VERSION ""

NS_ :

BS_:

BU_: EPS ABS ENGINE BCM RADAR CAMERA XXX

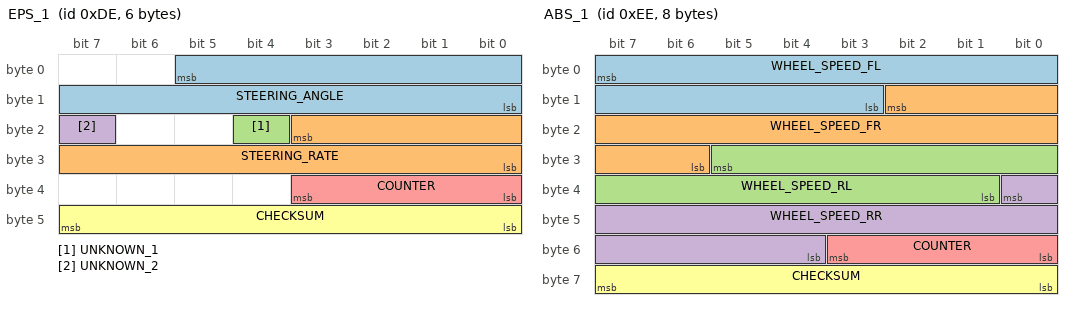
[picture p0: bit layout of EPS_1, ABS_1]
BO_ 222 EPS_1: 6 EPS
 SG_ STEERING_ANGLE : 5|14@0+ (0.1,-716.8) [-716.8|921.5] "deg" XXX
 SG_ STEERING_RATE : 19|12@0+ (1,-2000) [-2000|2095] "deg/s" XXX
 SG_ UNKNOWN_1 : 20|1@0+ (1,0) [0|1] "" XXX
 SG_ UNKNOWN_2 : 23|1@0+ (1,0) [0|1] "" XXX
 SG_ COUNTER : 35|4@0+ (1,0) [0|15] "" XXX
 SG_ CHECKSUM : 47|8@0+ (1,0) [0|255] "" XXX

BO_ 238 ABS_1: 8 ABS
 SG_ WHEEL_SPEED_FL : 7|13@0+ (0.017,0) [0|139.247] "m/s" XXX
 SG_ WHEEL_SPEED_FR : 10|13@0+ (0.017,0) [0|139.247] "m/s" XXX
 SG_ WHEEL_SPEED_RL : 29|13@0+ (0.017,0) [0|139.247] "m/s" XXX
 SG_ WHEEL_SPEED_RR : 32|13@0+ (0.017,0) [0|139.247] "m/s" XXX
 SG_ COUNTER : 51|4@0+ (1,0) [0|15] "" XXX
 SG_ CHECKSUM : 63|8@0+ (1,0) [0|255] "" XXX

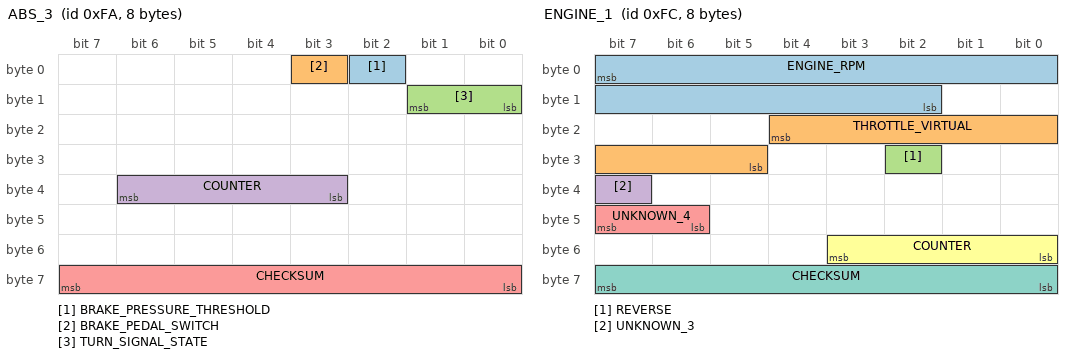
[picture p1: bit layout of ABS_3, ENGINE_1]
BO_ 250 ABS_3: 8 ABS
 SG_ BRAKE_PRESSURE_THRESHOLD : 2|1@0+ (1,0) [0|1] "" XXX
 SG_ BRAKE_PEDAL_SWITCH : 3|1@0+ (1,0) [0|1] "" XXX
 SG_ TURN_SIGNAL_STATE : 9|2@0+ (1,0) [0|3] "" XXX
 SG_ COUNTER : 38|4@0+ (1,0) [0|15] "" XXX
 SG_ CHECKSUM : 63|8@0+ (1,0) [0|255] "" XXX

BO_ 252 ENGINE_1: 8 ENGINE
 SG_ ENGINE_RPM : 7|14@0+ (1,0) [0|16383] "rev/min" XXX
 SG_ THROTTLE_VIRTUAL : 20|8@0+ (0.4,0) [0|102] "percent" XXX
 SG_ REVERSE : 26|1@0+ (1,0) [0|1] "" XXX
 SG_ UNKNOWN_3 : 39|1@0+ (1,0) [0|1] "" XXX
 SG_ UNKNOWN_4 : 46|2@1+ (1,0) [0|3] "" XXX
 SG_ COUNTER : 51|4@0+ (1,0) [0|15] "" XXX
 SG_ CHECKSUM : 63|8@0+ (1,0) [0|255] "" XXX

BO_ 496 ACCEL_PEDAL_DRIVER: 8 ENGINE
 SG_ ACCEL_PEDAL_DRIVER : 3|7@0+ (0.408,0) [0|51.8] "percent" XXX

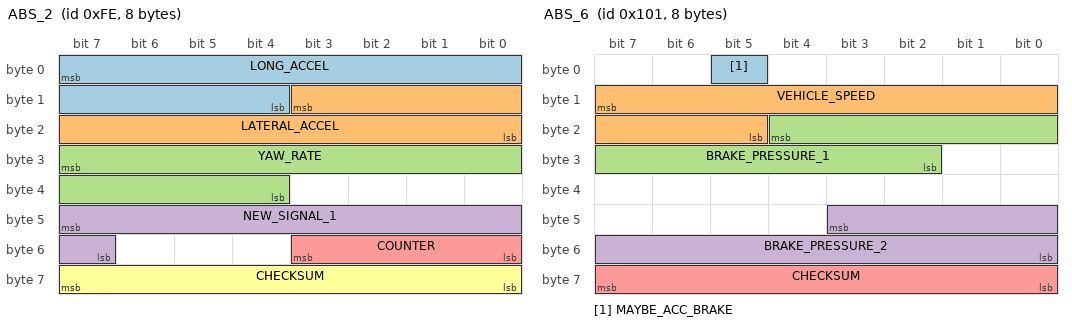
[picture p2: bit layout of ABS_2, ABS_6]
BO_ 254 ABS_2: 8 ABS
 SG_ LONG_ACCEL : 7|12@0+ (0.01,-20.48) [-20.48|20.47] "m/s2" XXX
 SG_ LATERAL_ACCEL : 11|12@0+ (0.01,-20.48) [-20.48|20.47] "m/s2" XXX
 SG_ YAW_RATE : 31|12@0+ (0.0014,-2.86) [-2.86|2.873] "rad/s" XXX
 SG_ NEW_SIGNAL_1 : 47|9@0+ (1,0) [0|511] "" XXX
 SG_ COUNTER : 51|4@0+ (1,0) [0|15] "" XXX
 SG_ CHECKSUM : 63|8@0+ (1,0) [0|255] "" XXX

BO_ 257 ABS_6: 8 ABS
 SG_ MAYBE_ACC_BRAKE : 5|1@0+ (1,0) [0|1] "" XXX
 SG_ VEHICLE_SPEED : 15|11@0+ (0.017,0) [0|34.799] "m/s" XXX
 SG_ BRAKE_PRESSURE_1 : 20|11@0+ (1,0) [0|2047] "" XXX
 SG_ BRAKE_PRESSURE_2 : 43|12@0+ (1,0) [0|4095] "" XXX
 SG_ CHECKSUM : 63|8@0+ (1,0) [0|255] "" XXX

BO_ 598 PARKING_BRAKE_STATUS: 8 XXX
 SG_ PARKING_BRAKE_ENGAGED : 3|1@0+ (1,0) [0|1] "" XXX

BO_ 599 SEATBELT_STATUS: 8 XXX
 SG_ SEATBELT_DRIVER_UNLATCHED : 21|1@0+ (1,0) [0|1] "" XXX

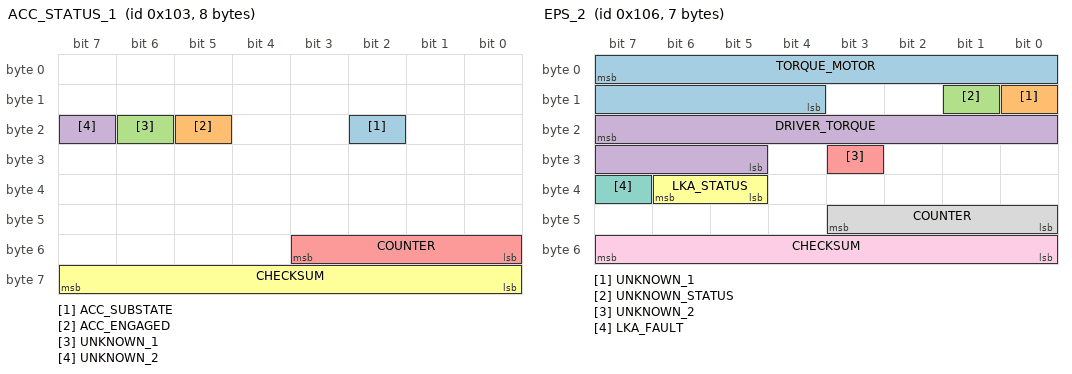
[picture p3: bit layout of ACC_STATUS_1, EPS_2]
BO_ 259 ACC_STATUS_1: 8 XXX
 SG_ ACC_SUBSTATE : 18|1@0+ (1,0) [0|1] "" XXX
 SG_ ACC_ENGAGED : 21|1@0+ (1,0) [0|1] "" XXX
 SG_ UNKNOWN_1 : 22|1@0+ (1,0) [0|1] "" XXX
 SG_ UNKNOWN_2 : 23|1@0+ (1,0) [0|1] "" XXX
 SG_ COUNTER : 51|4@0+ (1,0) [0|15] "" XXX
 SG_ CHECKSUM : 63|8@0+ (1,0) [0|255] "" XXX

BO_ 262 EPS_2: 7 EPS
 SG_ TORQUE_MOTOR : 7|12@0+ (1,-2000) [-2000|2095] "" XXX
 SG_ UNKNOWN_1 : 8|1@0+ (1,0) [0|1] "" XXX
 SG_ UNKNOWN_STATUS : 9|1@0+ (1,0) [0|1] "" XXX
 SG_ DRIVER_TORQUE : 23|11@0+ (1,-1024) [-1024|1023] "" XXX
 SG_ UNKNOWN_2 : 27|1@0+ (1,0) [0|1] "" XXX
 SG_ LKA_STATUS : 38|2@0+ (1,0) [0|3] "" XXX
 SG_ LKA_FAULT : 39|1@0+ (1,0) [0|1] "" XXX
 SG_ COUNTER : 43|4@0+ (1,0) [0|15] "" XXX
 SG_ CHECKSUM : 55|8@0+ (1,0) [0|255] "" XXX

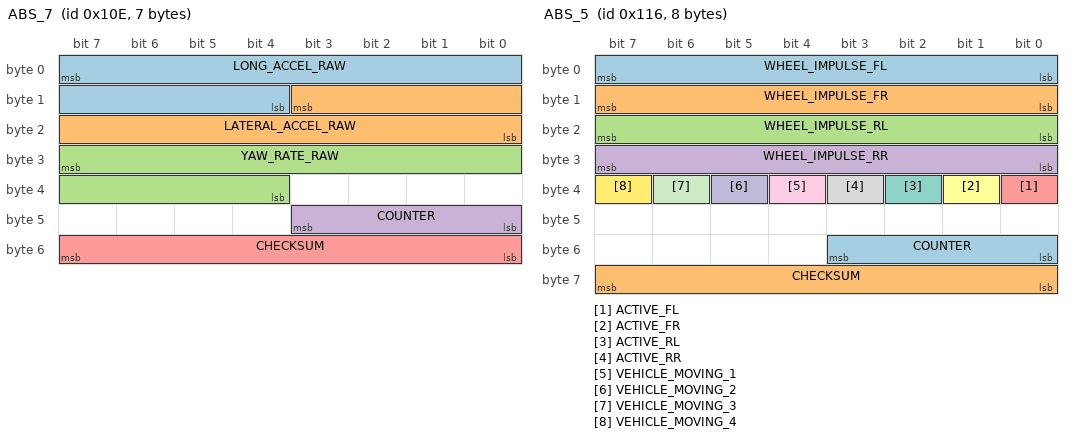
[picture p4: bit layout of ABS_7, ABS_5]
BO_ 270 ABS_7: 7 ABS
 SG_ LONG_ACCEL_RAW : 7|12@0+ (0.01,-20.48) [-20.48|20.47] "" XXX
 SG_ LATERAL_ACCEL_RAW : 11|12@0+ (0.01,-20.48) [-20.48|20.47] "" XXX
 SG_ YAW_RATE_RAW : 31|12@0+ (0.0014,-2.86) [-2.86|2.873] "" XXX
 SG_ COUNTER : 43|4@0+ (1,0) [0|15] "" XXX
 SG_ CHECKSUM : 55|8@0+ (1,0) [0|255] "" XXX

BO_ 278 ABS_5: 8 ABS
 SG_ WHEEL_IMPULSE_FL : 7|8@0+ (1,0) [0|255] "" XXX
 SG_ WHEEL_IMPULSE_FR : 15|8@0+ (1,0) [0|255] "" XXX
 SG_ WHEEL_IMPULSE_RL : 23|8@0+ (1,0) [0|255] "" XXX
 SG_ WHEEL_IMPULSE_RR : 31|8@0+ (1,0) [0|255] "" XXX
 SG_ ACTIVE_FL : 32|1@0+ (1,0) [0|1] "" XXX
 SG_ ACTIVE_FR : 33|1@0+ (1,0) [0|1] "" XXX
 SG_ ACTIVE_RL : 34|1@0+ (1,0) [0|1] "" XXX
 SG_ ACTIVE_RR : 35|1@0+ (1,0) [0|1] "" XXX
 SG_ VEHICLE_MOVING_1 : 36|1@0+ (1,0) [0|1] "" XXX
 SG_ VEHICLE_MOVING_2 : 37|1@0+ (1,0) [0|1] "" XXX
 SG_ VEHICLE_MOVING_3 : 38|1@0+ (1,0) [0|1] "" XXX
 SG_ VEHICLE_MOVING_4 : 39|1@0+ (1,0) [0|1] "" XXX
 SG_ COUNTER : 51|4@0+ (1,0) [0|15] "" XXX
 SG_ CHECKSUM : 63|8@0+ (1,0) [0|255] "" XXX

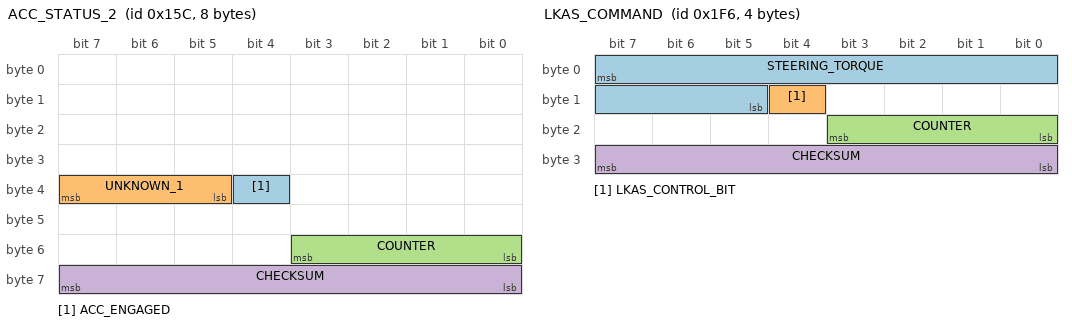
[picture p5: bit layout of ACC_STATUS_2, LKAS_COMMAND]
BO_ 348 ACC_STATUS_2: 8 XXX
 SG_ ACC_ENGAGED : 36|1@0+ (1,0) [0|1] "" XXX
 SG_ UNKNOWN_1 : 39|3@0+ (1,0) [0|7] "" XXX
 SG_ COUNTER : 51|4@0+ (1,0) [0|15] "" XXX
 SG_ CHECKSUM : 63|8@0+ (1,0) [0|255] "" XXX

BO_ 400 GEAR: 8 XXX
 SG_ PRNDL : 15|4@0+ (1,0) [0|15] "" XXX

BO_ 502 LKAS_COMMAND: 4 CAMERA
 SG_ STEERING_TORQUE : 7|11@0+ (1,-1024) [-1024|1023] "" XXX
 SG_ LKAS_CONTROL_BIT : 12|1@0+ (1,0) [0|1] "" XXX
 SG_ COUNTER : 19|4@0+ (1,0) [0|15] "" XXX
 SG_ CHECKSUM : 31|8@0+ (1,0) [0|255] "" XXX

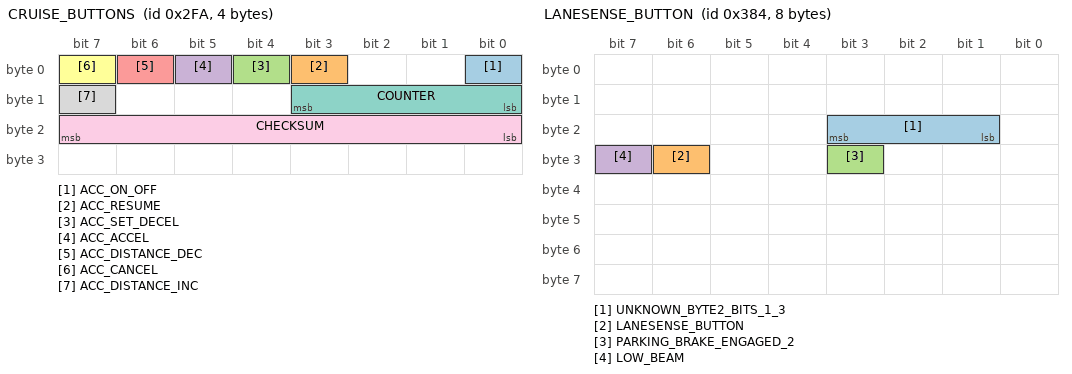
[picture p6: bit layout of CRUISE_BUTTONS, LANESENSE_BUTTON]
BO_ 762 CRUISE_BUTTONS: 4 BCM
 SG_ ACC_ON_OFF : 0|1@0+ (1,0) [0|1] "" XXX
 SG_ ACC_RESUME : 3|1@0+ (1,0) [0|1] "" XXX
 SG_ ACC_SET_DECEL : 4|1@0+ (1,0) [0|1] "" XXX
 SG_ ACC_ACCEL : 5|1@0+ (1,0) [0|1] "" XXX
 SG_ ACC_DISTANCE_DEC : 6|1@0+ (1,0) [0|1] "" XXX
 SG_ ACC_CANCEL : 7|1@0+ (1,0) [0|1] "" XXX
 SG_ COUNTER : 11|4@0+ (1,0) [0|15] "" XXX
 SG_ ACC_DISTANCE_INC : 15|1@0+ (1,0) [0|1] "" XXX
 SG_ CHECKSUM : 23|8@0+ (1,0) [0|255] "" XXX

BO_ 900 LANESENSE_BUTTON: 8 BCM
 SG_ UNKNOWN_BYTE2_BITS_1_3 : 19|3@0+ (1,0) [0|7] "" XXX
 SG_ LANESENSE_BUTTON : 30|1@0+ (1,0) [0|1] "" XXX
 SG_ PARKING_BRAKE_ENGAGED_2 : 27|1@0+ (1,0) [0|1] "" XXX
 SG_ LOW_BEAM : 31|1@0+ (1,0) [0|1] "" XXX

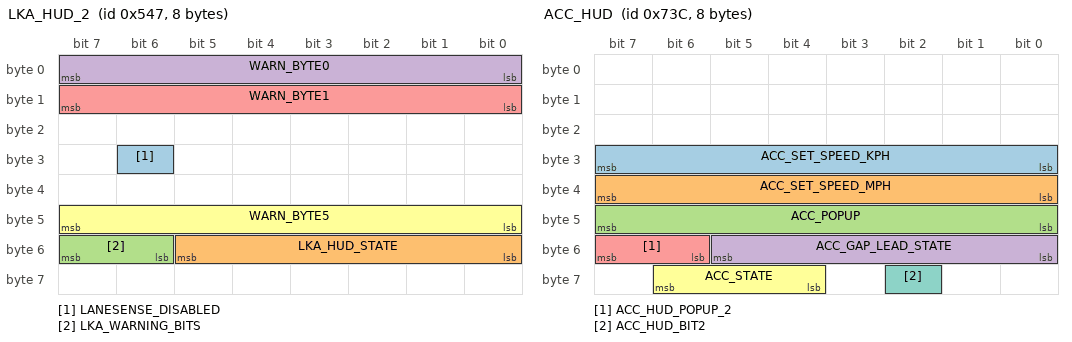
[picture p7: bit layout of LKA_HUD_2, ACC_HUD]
BO_ 1351 LKA_HUD_2: 8 CAMERA
 SG_ LANESENSE_DISABLED : 30|1@0+ (1,0) [0|1] "" XXX
 SG_ LKA_HUD_STATE : 53|6@0+ (1,0) [0|63] "" XXX
 SG_ LKA_WARNING_BITS : 55|2@0+ (1,0) [0|3] "" XXX
 SG_ WARN_BYTE0 : 7|8@0+ (1,0) [0|255] "" XXX
 SG_ WARN_BYTE1 : 15|8@0+ (1,0) [0|255] "" XXX
 SG_ WARN_BYTE5 : 47|8@0+ (1,0) [0|255] "" XXX

BO_ 1201 DOORS: 8 BCM
 SG_ DOOR_OPEN_FL : 0|1@0+ (1,0) [0|1] "" XXX
 SG_ DOOR_OPEN_FR : 15|1@0+ (1,0) [0|1] "" XXX

BO_ 1850 CLOCK: 6 BCM
 SG_ HOUR_BCD : 7|8@0+ (1,0) [0|255] "" XXX
 SG_ MINUTE_BCD : 15|8@0+ (1,0) [0|255] "" XXX

BO_ 1852 ACC_HUD: 8 XXX
 SG_ ACC_SET_SPEED_KPH : 31|8@0+ (1,0) [0|255] "km/h" XXX
 SG_ ACC_SET_SPEED_MPH : 39|8@0+ (1,0) [0|255] "mph" XXX
 SG_ ACC_POPUP : 47|8@0+ (1,0) [0|255] "" XXX
 SG_ ACC_GAP_LEAD_STATE : 53|6@0+ (1,0) [0|63] "" XXX
 SG_ ACC_HUD_POPUP_2 : 55|2@0+ (1,0) [0|3] "" XXX
 SG_ ACC_STATE : 62|3@0+ (1,0) [0|7] "" XXX
 SG_ ACC_HUD_BIT2 : 58|1@0+ (1,0) [0|1] "" XXX

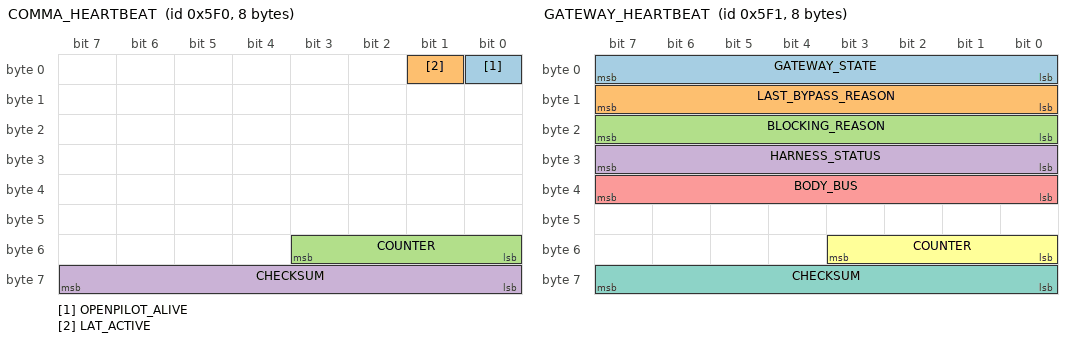
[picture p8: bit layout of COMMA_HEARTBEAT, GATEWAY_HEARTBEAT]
BO_ 1520 COMMA_HEARTBEAT: 8 XXX
 SG_ OPENPILOT_ALIVE : 0|1@0+ (1,0) [0|1] "" XXX
 SG_ LAT_ACTIVE : 1|1@0+ (1,0) [0|1] "" XXX
 SG_ COUNTER : 51|4@0+ (1,0) [0|15] "" XXX
 SG_ CHECKSUM : 63|8@0+ (1,0) [0|255] "" XXX

BO_ 1521 GATEWAY_HEARTBEAT: 8 XXX
 SG_ GATEWAY_STATE : 7|8@0+ (1,0) [0|255] "" XXX
 SG_ LAST_BYPASS_REASON : 15|8@0+ (1,0) [0|255] "" XXX
 SG_ BLOCKING_REASON : 23|8@0+ (1,0) [0|255] "" XXX
 SG_ HARNESS_STATUS : 31|8@0+ (1,0) [0|255] "" XXX
 SG_ BODY_BUS : 39|8@0+ (1,0) [0|255] "" XXX
 SG_ COUNTER : 51|4@0+ (1,0) [0|15] "" XXX
 SG_ CHECKSUM : 63|8@0+ (1,0) [0|255] "" XXX

BO_ 1444 BSM_1: 8 XXX
 SG_ RIGHT_STATUS : 12|1@0+ (1,0) [0|1] "" XXX
 SG_ LEFT_STATUS : 13|1@0+ (1,0) [0|1] "" XXX

BO_ 1449 GEAR_2: 8 XXX
 SG_ PARKING_BRAKE_ENGAGED : 15|1@0+ (1,0) [0|1] "" XXX
 SG_ PRNDL : 23|3@0+ (1,0) [0|7] "" XXX

BO_ 1854 STEERING_LEVERS: 4 BCM
 SG_ TURN_SIGNALS : 17|2@0+ (1,0) [0|3] "" XXX

CM_ "2023 Jeep Renegade (FCA small-wide / SUSW platform). EPS/ABS/ENGINE/LKAS definitions carried over from fca_giorgio.dbc and chrysler_cusw.dbc where the FCA CRC-8 validates on this car; CRUISE_BUTTONS, ACC_STATUS_1/2 decoded from raw CAN C captures (see docs/susw-dbc-notes.md).";
CM_ BO_ 259 "Raw CAN C only, 100 Hz. ACC_ENGAGED tracks stock ACC engage/resume and cancel (button or brake) exactly.";
CM_ BO_ 348 "Raw CAN C only, 10 Hz while ACC is disengaged and 50 Hz while engaged. ACC_ENGAGED duplicates ACC_STATUS_1.";
CM_ BO_ 502 "CH. Camera to EPS. 4 bytes on this platform (CUSW layout), not Giorgio's 8.";
CM_ SG_ 502 LKAS_CONTROL_BIT "1 = camera has lanes and is armed to intervene (cluster car icon green); 99.8 % agreement with LKA_HUD_2 lanes-detected state on route 000000d8. Not torque-active: only 9 % of set frames carry torque. Flickers faster than the icon (runs down to 0.16 s) - cluster debounces.";
CM_ BO_ 762 "Raw CAN C only, 50 Hz, from BCM (SCCM_CRS_CTRL). 4 bytes; byte 1 = counter (low nibble) + DISTANCE_INC (bit7); byte 3 always 0. CHECKSUM = FCA CRC-8 (poly 0x1D, init 0xFF, xor 0xFF) over bytes 0-1. Bit map differs from CUSW.";
CM_ SG_ 762 ACC_DISTANCE_DEC "gap decrease button (byte0 bit6)";
CM_ SG_ 762 ACC_DISTANCE_INC "gap increase button (byte1 bit7)";
CM_ SG_ 762 ACC_SET_DECEL "SET when not engaged, speed - when engaged";
CM_ SG_ 762 ACC_ACCEL "RES+ / speed + when engaged";
CM_ SG_ 259 ACC_SUBSTATE "1 was observed only while ACC_ENGAGED; it resets after some disengagements, including eight falling edges after ACC_ENGAGED cleared. Meaning TBD.";
CM_ SG_ 252 THROTTLE_VIRTUAL "Formerly ACCEL_PEDAL. This is the PCM's commanded/virtual pedal: > 0 on 97.5 % of ACC-engaged frames (routes 000000e7/000000d8) and led by the 0x15C ACC accel request; it also carries the driver press (parked marks 134/135). Not a driver-only gas signal.";
CM_ BO_ 496 "Raw CAN C and CH, ~50 Hz, no counter or checksum; bytes 2-7 always 0. Driver accelerator pedal: corr +0.9998 with THROTTLE_VIRTUAL while ACC is off, exactly 0 on all 128,528 settled ACC-engaged frames of routes 000000e7 and 000000d8, nonzero on 98.6 % of the parked pedal press (marks 134/135). Gain 0.408 %/count is fitted against THROTTLE_VIRTUAL, not pedal travel.";
CM_ SG_ 257 MAYBE_ACC_BRAKE "may correlate with ACC-actuated braking";
CM_ SG_ 250 TURN_SIGNAL_STATE "byte1 bits 0-1: 2 left, 1 right, 0 off. Hazards are not represented here; use STEERING_LEVERS.TURN_SIGNALS for hazards.";
CM_ BO_ 598 "Raw CAN C only. byte0 bit3 is 1 while the electronic parking brake is ENGAGED and 0 while released - the opposite of the earlier reading. The parked sweep was ON->OFF->ON, not OFF->ON->OFF ('the parking brake is already on', 490.1 s of route 000000e7); the bit also goes 0 at drive-away (869.84 s) and 1 at the narrated 'Parking brake on' (3513.95 s), and matches the two CAN CH copies frame for frame.";
CM_ BO_ 400 "Raw CAN C only, 20 Hz. byte1 high nibble followed P=1, R=2, N=3, D=4, P=1 exactly during the isolated parked PRNDL sweep in collection-run-1.";
CM_ BO_ 1201 "Raw CAN C and CH, 2 Hz plus on change. Front-door sweep: byte0 bit0 = driver/front-left open; byte1 bit7 = passenger/front-right open. Rear doors were not exercised and remain undefined.";
CM_ BO_ 1854 "Raw CAN C and CH, about 4 Hz plus on change. byte2 low two bits: 0 off, 1 right, 2 left, 3 hazards; confirmed by the isolated parked sweep in collection-run-1.";
CM_ BO_ 1444 "Raw CAN C only, 1 Hz plus on change. Isolated traffic events in collection-run-1 confirmed byte1 bit4 = right blind spot and bit5 = left blind spot; both bits were observed simultaneously.";
CM_ SG_ 262 TORQUE_MOTOR "EPS motor torque. During the isolated parked steering sweep it correlated 0.976 with DRIVER_TORQUE; during LKAS actuation it followed commanded torque with the expected lower scale.";
CM_ SG_ 262 LKA_STATUS "0 inactive, 2 armed/accepted. Value 2 agreed with LKAS_COMMAND.LKAS_CONTROL_BIT on 99.95 % of frames and was present for essentially all green/yellow HUD states in collection-run-1.";
CM_ BO_ 1351 "CH, 4 Hz, camera HUD status. byte6 drives the cluster car icon: 0x02 grey (on, no lanes), 0x0c green (lanes detected, active), 0x14/0x10 yellow intervention (0x14 coincides with positive LKAS_COMMAND torque, 0x10 with the opposite side), 0xcc seen at departure warnings in route 00000003.";
CM_ SG_ 1351 LANESENSE_DISABLED "toggled with the LaneSense button in route 00000003; 0 for all of route 000000ca where LaneSense was on throughout";
CM_ SG_ 1351 WARN_BYTE0 "0 or 6, only during departure warnings";
CM_ SG_ 1351 WARN_BYTE1 "0/64/128 toggling fast during departure warnings (chime/haptic pattern?)";
CM_ SG_ 1351 WARN_BYTE5 "0 or 64, only during departure warnings";
CM_ SG_ 900 LANESENSE_BUTTON "1 while the LaneSense button is held; confirmed on route 000000d8 (8 presses incl. two 10 s holds), each followed by LKA_HUD_2.LANESENSE_DISABLED toggling";
CM_ SG_ 900 UNKNOWN_BYTE2_BITS_1_3 "Former lead-vehicle candidate; 159 transitions and poor edge specificity in route 000000d8. No semantic assignment.";
CM_ BO_ 1852 "Raw CAN C only. Sent at 1 Hz and immediately on change. Cluster ACC display. bytes 0-2 constant (0x00 0x9f 0xc0).";
CM_ SG_ 1852 ACC_SET_SPEED_MPH "0 when no set speed; 34..40, 28..40 etc. match the narrated set speeds press for press";
CM_ SG_ 1852 ACC_POPUP "5-second cluster popup code: 14 ACC on, 15 set/engaged, 17 cancelled, 13 seen before ACC enabled; 0 otherwise";
CM_ SG_ 1852 ACC_GAP_LEAD_STATE "byte6 bits 0-5 enum: 6-9 = lead present at gaps 1-4; 10-13 = no lead at gaps 1-4. Lead acquire/loss changes the value by 4 without a gap-button press. Values 15/17 occur during standby/cancel transitions and remain unmapped.";
CM_ SG_ 1852 ACC_HUD_POPUP_2 "byte6 bits 6-7 set for ~5 s after ACC events";
CM_ SG_ 1852 ACC_STATE "0 off, 1 on/ready (after ACC on button, no set speed), 2 engaged, 5 standby after cancel (set speed retained), 3 and 4 one-frame transitions (cancel, engage)";
CM_ BO_ 1850 "Raw CAN C only, 1 Hz. byte0 = hour, byte1 = minute, BCD, local time";
CM_ SG_ 1351 LKA_HUD_STATE "byte6 bits 0-5, enumerated (bit-field readings do not fit all values): 2 grey car (LaneSense on, no lanes), 12 green (lanes acquired, armed), 16 yellow left departure (negative LKAS torque), 20 yellow right departure (positive torque), 12 also held during the hands-off warning (0xcc); 8/22/24/0 seen rarely, unmapped";
CM_ SG_ 1351 LKA_WARNING_BITS "byte6 bits 6-7: 3 during the captured combined lane-departure + hands-off warning (0xcc with green state, 0xd0 with yellow-left); 0 otherwise. Hands-off-only behavior was not captured.";
CM_ SG_ 222 STEERING_RATE "1 count = 1 deg/s, not 0.5: the raw value rests at exactly 2000 and fits raw = 1.01*d(STEERING_ANGLE)/dt + 2000 (route e7 n=54314 slope 1.012 intercept 2000.1, route d8 n=54872 slope 1.025 intercept 1999.8). Correlation with the differentiated angle 0.988 / 0.980, median residual 0.053 deg/s. Corrected peaks -436..+394 deg/s.";
CM_ SG_ 254 YAW_RATE "Left-positive, same convention as STEERING_ANGLE and LATERAL_ACCEL. With the previously declared negative factor the value correlated -0.972 (e7, n=225k above 5 m/s) / -0.976 (d8) with the steering angle and went negative in every narrated left turn, while LATERAL_ACCEL went positive. The positive factor makes all three agree; the resulting gain yaw ~= 3.7e-4 * angle * speed implies an effective steering ratio near 18, plausible for a 2.57 m wheelbase.";
CM_ SG_ 270 YAW_RATE_RAW "Same sign correction as ABS_2.YAW_RATE, see the comment there.";
CM_ SG_ 278 VEHICLE_MOVING_1 "Bits 36-39 were previously named FORWARD_1/REVERSE_1/FORWARD_2/REVERSE_2. They are not direction: all four carry the same 68.9 % duty and agree with ABS_6.VEHICLE_SPEED > 0 on 99.76 % of frames, so they are a vehicle-moving flag. Direction lives in the ACTIVE_* bits.";
CM_ SG_ 278 ACTIVE_FR "Set on 99.07 % of reverse-and-moving frames and on 0.03 % of forward-and-moving frames (1609 set frames, 93.0 % inside an ENGINE_1.REVERSE window), so ACTIVE_FL/ACTIVE_FR look like a front-axle (forward, backward) rolling-direction pair rather than a per-wheel active flag. Not renamed: the per-wheel semantics are not proven, and this reports wheel rotation, not the selected gear.";
CM_ BO_ 1520 "Private fusion bus only (comma bus 1), not a vehicle message. Sent by openpilot at 10 Hz; the RPGW gateway treats a valid frame (DLC 8, FCA CRC-8 over bytes 0-6, moving counter) as the opt-in for INTERCEPT and returns to BYPASS when it stops. ID chosen outside every address seen on fusion (0x200-0x3c0 radar slots, 0x7a9, 29-bit diagnostics) and outside the CAN C whitelist.";
CM_ BO_ 1521 "Private fusion bus only (comma bus 1), not a vehicle message. Sent by the RPGW gateway at 5 Hz while it has heard COMMA_HEARTBEAT within the last 5 s. GATEWAY_STATE 0 = BYPASS, 1 = INTERCEPT; reason codes per board/gateway.h in panda.";
CM_ BO_ 599 "CAN CH (comma bus 0 and 2) and raw CAN C, 10 Hz, DLC 8. Byte 2 is 0x10 with the driver belt latched and 0x30 unlatched; 0xff for the last few frames after ignition-off (invalid, not a belt state). Bytes 1 and 3 are constant 0xfe / 0x40 and byte 2 bit 4 is constantly 1 on both routes. Over the 490 s parked baseline of route 000000e7 this is the only CH bit that follows the narrated latch/unlatch/latch sequence (202.69, 212.44, 218.25 s) with no other change; raw-C 0x5a7 byte0 bit5 is an exact duplicate. Route 000000d8 independently shows unlatched 0-28.6 s, latched for the whole drive, unlatched again 3205.4 s right after shifting to P and setting the parking brake. The passenger belt is NOT represented: four isolated passenger latch/unlatch actions (236-249 s) move no bit on either bus, most likely because the seat was unoccupied.";
CM_ SG_ 599 SEATBELT_DRIVER_UNLATCHED "1 = driver belt unlatched. Drives CarState.seatbeltUnlatched directly - it is on CAN CH, so it needs no RPGW forwarding.";
CM_ BO_ 1449 "CAN CH only (absent from raw CAN C), 1 Hz plus on change, DLC 8. Independent CH-side gear and parking-brake report; unlike GEAR 0x190 it is visible to the comma without RPGW forwarding.";
CM_ SG_ 1449 PRNDL "Byte 2 bits 5-7, same enum as GEAR.PRNDL on 0x190: 1 P, 2 R, 3 N, 4 D. Frame-level agreement with the raw-C 0x190 field is 99.775 % over 3550 frames of route 000000e7 (all 8 disagreements are shift transients where 0x190 momentarily reads 0). Value 6 is the manual/AutoStick gate, from the narrated park/reverse/neutral/drive/manual/drive/park sweep at 543-570 s of route 000000d8. Values 5 and 7 were never observed; bits 0-4 of byte 2 are always zero.";
CM_ SG_ 1449 PARKING_BRAKE_ENGAGED "1 = electronic parking brake engaged (byte 1 is 0x8c engaged, 0x0c released). Edges 496.00 released / 500.18 engaged (parked marks 129 and 128, which were ON->OFF->ON: the brake was already on), 871.02 released at drive-away, 3512.74 engaged at the end of the route. Agrees with LANESENSE_BUTTON.PARKING_BRAKE_ENGAGED_2 on 100.000 % of 14127 frames.";
CM_ SG_ 900 PARKING_BRAKE_ENGAGED_2 "Byte 3 bit 3, 1 = electronic parking brake engaged. Agrees with GEAR_2.PARKING_BRAKE_ENGAGED on 100.000 % of route 000000e7 frames and 99.992 % of route 000000d8, duty 25.0 % / 16.0 %.";
CM_ SG_ 900 LOW_BEAM "Byte 3 bit 7, 1 = low beams lit. Unique match over the 490 s parked baseline for the four narrated headlamp-knob actions (374.00 on, 385.75 off to parking, 391.75 on, 401.24 off in auto). It reports lamps lit, not switch position: the off->parking step produces no change anywhere, and no field on either bus follows all six knob positions. Set for only 0.60 % of route 000000e7 and 0.36 % of 000000d8, both daytime drives.";
VAL_ 250 TURN_SIGNAL_STATE 0 "OFF" 1 "RIGHT" 2 "LEFT" ;
VAL_ 262 LKA_STATUS 0 "INACTIVE" 2 "ARMED" ;
VAL_ 400 PRNDL 1 "P" 2 "R" 3 "N" 4 "D" ;
VAL_ 1351 LKA_HUD_STATE 2 "GREY_NO_LANES" 12 "GREEN_ARMED" 16 "YELLOW_LEFT" 20 "YELLOW_RIGHT" ;
VAL_ 1449 PRNDL 1 "P" 2 "R" 3 "N" 4 "D" 6 "MANUAL" ;
VAL_ 1852 ACC_GAP_LEAD_STATE 6 "LEAD_GAP_1" 7 "LEAD_GAP_2" 8 "LEAD_GAP_3" 9 "LEAD_GAP_4" 10 "NO_LEAD_GAP_1" 11 "NO_LEAD_GAP_2" 12 "NO_LEAD_GAP_3" 13 "NO_LEAD_GAP_4" ;
VAL_ 1854 TURN_SIGNALS 0 "OFF" 1 "RIGHT" 2 "LEFT" 3 "HAZARDS" ;
VAL_ 1521 GATEWAY_STATE 0 "BYPASS" 1 "INTERCEPT" ;
